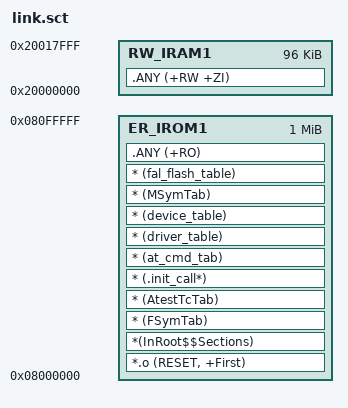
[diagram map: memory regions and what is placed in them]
; *************************************************************
; *** Scatter-Loading Description File generated by uVision ***
; *************************************************************

LR_IROM1 0x08000000 0x00100000  {    ; load region size_region
  ER_IROM1 0x08000000 0x00100000  {  ; load address = execution address
   *.o (RESET, +First)
   *(InRoot$$Sections)
   * (FSymTab)
   * (AtestTcTab)
   * (.init_call*)
   * (at_cmd_tab)
   * (driver_table)
   * (device_table)
   * (MSymTab)
   * (fal_flash_table)
   .ANY (+RO)
  }
  RW_IRAM1 0x20000000 0x00018000  {  ; RW data
   .ANY (+RW +ZI)
  }
}

